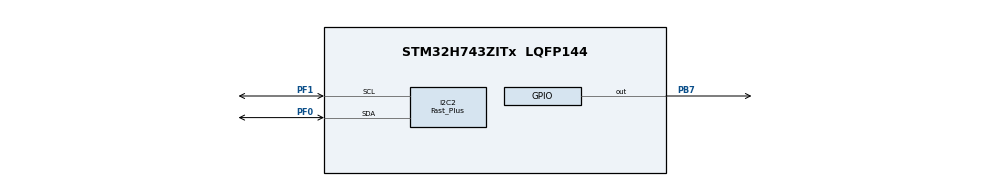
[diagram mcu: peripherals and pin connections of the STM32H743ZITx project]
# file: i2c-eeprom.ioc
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I2C2.I2C_Speed_Mode=I2C_Fast_Plus
I2C2.Timing=0x00401242
Mcu.Family=STM32H7
Mcu.Name=STM32H743ZITx
Mcu.Package=LQFP144
NVIC.PriorityGroup=NVIC_PRIORITYGROUP_4
NVIC.TIM8_UP_TIM13_IRQn=true\:0\:0\:false\:false\:true\:false\:true
NVIC.TimeBase=TIM8_UP_TIM13_IRQn
NVIC.TimeBaseIP=TIM13
PA13\ (JTMS/SWDIO).Mode=Serial_Wire
PA13\ (JTMS/SWDIO).Signal=DEBUG_JTMS-SWDIO
PA14\ (JTCK/SWCLK).Mode=Serial_Wire
PA14\ (JTCK/SWCLK).Signal=DEBUG_JTCK-SWCLK
PB7.Signal=GPIO_Output
PF0.GPIO_PuPd=GPIO_PULLUP
PF0.Mode=I2C
PF0.Signal=I2C2_SDA
PF1.GPIO_PuPd=GPIO_PULLUP
PF1.Mode=I2C
PF1.Signal=I2C2_SCL
PH0-OSC_IN\ (PH0).Mode=HSE-External-Oscillator
PH0-OSC_IN\ (PH0).Signal=RCC_OSC_IN
PH1-OSC_OUT\ (PH1).Mode=HSE-External-Oscillator
PH1-OSC_OUT\ (PH1).Signal=RCC_OSC_OUT
ProjectManager.HeapSize=0x2000
ProjectManager.StackSize=0x4000
ProjectManager.TargetToolchain=EWARM V8.32
RCC.ADCFreq_Value=12750000
RCC.APB1Freq_Value=100000000
RCC.APB2Freq_Value=100000000
RCC.APB3Freq_Value=100000000
RCC.APB4Freq_Value=100000000
RCC.CortexFreq_Value=400000000
RCC.D1PPRE=RCC_APB3_DIV2
RCC.D2PPRE1=RCC_APB1_DIV2
RCC.D2PPRE2=RCC_APB2_DIV2
RCC.D3PPRE=RCC_APB4_DIV2
RCC.DIVM1=1
RCC.DIVM2=2
RCC.DIVM3=1
RCC.DIVN1=100
RCC.DIVN2=51
RCC.DIVN3=20
RCC.DIVP2=16
RCC.HCLKFreq_Value=200000000
RCC.HPRE=RCC_HCLK_DIV2
RCC.HSE_VALUE=8000000
RCC.PLLSourceVirtual=RCC_PLLSOURCE_HSE
RCC.PWR_Regulator_Voltage_Scale=PWR_REGULATOR_VOLTAGE_SCALE1
RCC.SYSCLKFreq_VALUE=400000000
RCC.SYSCLKSource=RCC_SYSCLKSOURCE_PLLCLK
RCC.USBFreq_Value=400000000
VP_SYS_VS_tim13.Mode=TIM13
board=custom

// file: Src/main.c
/* USER CODE BEGIN Header */
/**
  ******************************************************************************
  * @file           : main.c
  * @brief          : Main program body
  ******************************************************************************
  * @attention
  *
  * <h2><center>&copy; Copyright (c) 2021 STMicroelectronics.
  * All rights reserved.</center></h2>
  *
  * This software component is licensed by ST under BSD 3-Clause license,
  * the "License"; You may not use this file except in compliance with the
  * License. You may obtain a copy of the License at:
  *                        opensource.org/licenses/BSD-3-Clause
  *
  ******************************************************************************
  */
/* USER CODE END Header */

#include "main.h"

/* USER CODE BEGIN Includes */
#include "user_run.h"
/* USER CODE END Includes */

I2C_HandleTypeDef hi2c2;

void SystemClock_Config(void);

static void MX_GPIO_Init(void);

static void MX_I2C2_Init(void);

int main(void)
{

    /* MCU Configuration--------------------------------------------------------*/

    /* Reset of all peripherals, Initializes the Flash interface and the Systick. */
    HAL_Init();

    /* Configure the system clock */
    SystemClock_Config();

    /* Initialize all configured peripherals */
    MX_GPIO_Init();
    MX_I2C2_Init();

    /* Infinite loop */

    /* USER CODE BEGIN 3 */
    userRun();
    /* USER CODE END 3 */
}

void SystemClock_Config(void)
{
    RCC_OscInitTypeDef RCC_OscInitStruct = {0};
    RCC_ClkInitTypeDef RCC_ClkInitStruct = {0};
    RCC_PeriphCLKInitTypeDef PeriphClkInitStruct = {0};

    /** Supply configuration update enable
    */
    HAL_PWREx_ConfigSupply(PWR_LDO_SUPPLY);
    /** Configure the main internal regulator output voltage
    */
    __HAL_PWR_VOLTAGESCALING_CONFIG(PWR_REGULATOR_VOLTAGE_SCALE1);

    while (!__HAL_PWR_GET_FLAG(PWR_FLAG_VOSRDY))
    {
    }
    /** Initializes the CPU, AHB and APB busses clocks
    */
    RCC_OscInitStruct.OscillatorType = RCC_OSCILLATORTYPE_HSE;
    RCC_OscInitStruct.HSEState = RCC_HSE_ON;
    RCC_OscInitStruct.PLL.PLLState = RCC_PLL_ON;
    RCC_OscInitStruct.PLL.PLLSource = RCC_PLLSOURCE_HSE;
    RCC_OscInitStruct.PLL.PLLM = 1;
    RCC_OscInitStruct.PLL.PLLN = 100;
    RCC_OscInitStruct.PLL.PLLP = 2;
    RCC_OscInitStruct.PLL.PLLQ = 2;
    RCC_OscInitStruct.PLL.PLLR = 2;
    RCC_OscInitStruct.PLL.PLLRGE = RCC_PLL1VCIRANGE_3;
    RCC_OscInitStruct.PLL.PLLVCOSEL = RCC_PLL1VCOWIDE;
    RCC_OscInitStruct.PLL.PLLFRACN = 0;
    if (HAL_RCC_OscConfig(&RCC_OscInitStruct) != HAL_OK)
    {
        Error_Handler();
    }
    /** Initializes the CPU, AHB and APB busses clocks
    */
    RCC_ClkInitStruct.ClockType = RCC_CLOCKTYPE_HCLK | RCC_CLOCKTYPE_SYSCLK
                                  | RCC_CLOCKTYPE_PCLK1 | RCC_CLOCKTYPE_PCLK2
                                  | RCC_CLOCKTYPE_D3PCLK1 | RCC_CLOCKTYPE_D1PCLK1;
    RCC_ClkInitStruct.SYSCLKSource = RCC_SYSCLKSOURCE_PLLCLK;
    RCC_ClkInitStruct.SYSCLKDivider = RCC_SYSCLK_DIV1;
    RCC_ClkInitStruct.AHBCLKDivider = RCC_HCLK_DIV2;
    RCC_ClkInitStruct.APB3CLKDivider = RCC_APB3_DIV2;
    RCC_ClkInitStruct.APB1CLKDivider = RCC_APB1_DIV2;
    RCC_ClkInitStruct.APB2CLKDivider = RCC_APB2_DIV2;
    RCC_ClkInitStruct.APB4CLKDivider = RCC_APB4_DIV2;

    if (HAL_RCC_ClockConfig(&RCC_ClkInitStruct, FLASH_LATENCY_2) != HAL_OK)
    {
        Error_Handler();
    }
    PeriphClkInitStruct.PeriphClockSelection = RCC_PERIPHCLK_I2C2;
    PeriphClkInitStruct.I2c123ClockSelection = RCC_I2C123CLKSOURCE_D2PCLK1;
    if (HAL_RCCEx_PeriphCLKConfig(&PeriphClkInitStruct) != HAL_OK)
    {
        Error_Handler();
    }
}

static void MX_I2C2_Init(void)
{

    hi2c2.Instance = I2C2;
    hi2c2.Init.Timing = 0x00401242;
    hi2c2.Init.OwnAddress1 = 0;
    hi2c2.Init.AddressingMode = I2C_ADDRESSINGMODE_7BIT;
    hi2c2.Init.DualAddressMode = I2C_DUALADDRESS_DISABLE;
    hi2c2.Init.OwnAddress2 = 0;
    hi2c2.Init.OwnAddress2Masks = I2C_OA2_NOMASK;
    hi2c2.Init.GeneralCallMode = I2C_GENERALCALL_DISABLE;
    hi2c2.Init.NoStretchMode = I2C_NOSTRETCH_DISABLE;
    if (HAL_I2C_Init(&hi2c2) != HAL_OK)
    {
        Error_Handler();
    }
    /** Configure Analogue filter
    */
    if (HAL_I2CEx_ConfigAnalogFilter(&hi2c2, I2C_ANALOGFILTER_ENABLE) != HAL_OK)
    {
        Error_Handler();
    }
    /** Configure Digital filter
    */
    if (HAL_I2CEx_ConfigDigitalFilter(&hi2c2, 0) != HAL_OK)
    {
        Error_Handler();
    }
    /** I2C Enable Fast Mode Plus
    */
    HAL_I2CEx_EnableFastModePlus(I2C_FASTMODEPLUS_I2C2);

}

static void MX_GPIO_Init(void)
{
    GPIO_InitTypeDef GPIO_InitStruct = {0};

    /* GPIO Ports Clock Enable */
    __HAL_RCC_GPIOF_CLK_ENABLE();
    __HAL_RCC_GPIOH_CLK_ENABLE();
    __HAL_RCC_GPIOA_CLK_ENABLE();
    __HAL_RCC_GPIOB_CLK_ENABLE();

    /*Configure GPIO pin Output Level */
    HAL_GPIO_WritePin(GPIOB, GPIO_PIN_7, GPIO_PIN_RESET);

    /*Configure GPIO pin : PB7 */
    GPIO_InitStruct.Pin = GPIO_PIN_7;
    GPIO_InitStruct.Mode = GPIO_MODE_OUTPUT_PP;
    GPIO_InitStruct.Pull = GPIO_NOPULL;
    GPIO_InitStruct.Speed = GPIO_SPEED_FREQ_LOW;
    HAL_GPIO_Init(GPIOB, &GPIO_InitStruct);

}

void HAL_TIM_PeriodElapsedCallback(TIM_HandleTypeDef *htim)
{
    if (htim->Instance == TIM13)
    {
        HAL_IncTick();
    }
}

void Error_Handler(void)
{
}

/************************ (C) COPYRIGHT STMicroelectronics *****END OF FILE****/
